# XMC4100 register map
Vendor: Infineon; File version: 1.5.2 (Reference Manual v1.5)
CPU: CM4 r2p0, little endian, MPU, FPU, 6 interrupt priority bits
Registers are 32-bit, read-write, reset 0x0 unless marked. A register's access mark holds for its fields unless they carry their own. Offsets are from the block's base; [hi:lo] are bit positions; {n}, {i} and the like mark numbered series; 'fields as' and 'values as' point back to an identical list.

## HRPWM0_CSG0 — High Resolution PWM Unit
Base 0x40020A00
Same registers: HRPWM0_CSG1 0x40020B00, HRPWM0_CSG2 0x40020C00
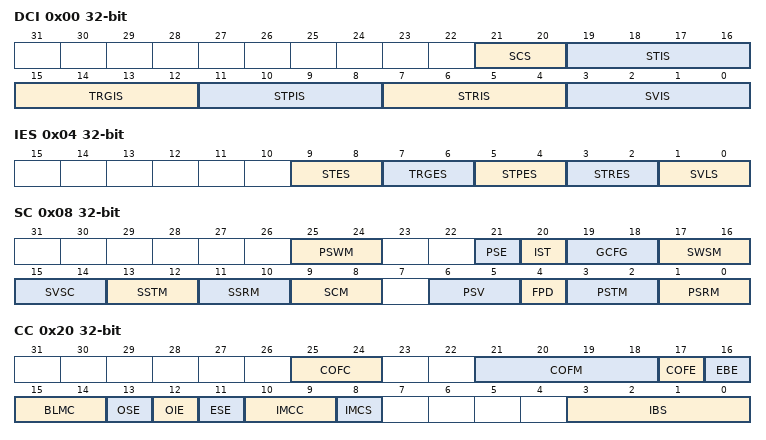
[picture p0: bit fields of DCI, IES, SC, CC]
0x00 DCI — External input selection
  [21:20] SCS — Slope generation clock selection
    0=HRPWMx.MCLK (Module clock is used); 1=HRPWMx.ECLKA (External clock is used); 2=HRPWMx.ECLKB (External clock is used); 3=HRPWMx.ECLKC (External clock is used)
  [19:16] STIS — External shadow request enable input selection
  [15:12] TRGIS — External conversion trigger input selection
  [11:8] STPIS — Slope generation stop control input selection
  [7:4] STRIS — Slope generation start control input selection
  [3:0] SVIS — Value Selector input selection
    0=HRPWMx.SyIA; 1=HRPWMx.SyIB; 2=HRPWMx.SyIC; 3=HRPWMx.SyID; 4=HRPWMx.SyIE; 5=HRPWMx.SyIF; 6=HRPWMx.SyIG; 7=HRPWMx.SyIH; 8=HRPWMx.SyII; 9=HRPWMx.SyIJ; 10=HRPWMx.SyIK; 11=HRPWMx.SyIL; 12=HRPWMx.SyIM; 13=HRPWMx.SyIN; 14=HRPWMx.SyIO; 15=HRPWMx.SyIP
0x04 IES — External input selection
  [9:8] STES — External shadow transfer enable edge selection
    0=Function disabled; 1=Active on rising edge; 2=Active on falling edge; 3=Active on both edges
  [7:6] TRGES — External trigger function edge selection
    values as STES
  [5:4] STPES — External stop function edge selection
    values as STES
  [3:2] STRES — External start function edge selection
    values as STES
  [1:0] SVLS — External value switch function level selection
    0=Function disabled; 1=Active when input is HIGH; 2=Active when input is LOW
0x08 SC — Slope generation control
  [25:24] PSWM — Pulse swallow window mode
    0=16 clock cycle window; 1=32 clock cycle window; 2=64 clock cycle window
  [21] PSE — Pulse swallow enable
    0=Pulse swallow disabled; 1=Pulse swallow enabled
  [20] IST — Immediate shadow transfer
  [19:18] GCFG — Slope step gain configuration
    0=Each slope step has an increment/decrement of 1; 1=Each slope step has an increment/decrement of 2; 2=Each slope step has an increment/decrement of 4; 3=Each slope step has an increment/decrement of 8
  [17:16] SWSM — Initial DAC start mode
    0=CSGyDSV2This register contains the actual value used for the DSV2 reference. is fed to the DAC and initial conversion trigger is generated.; 1=CSGyDSV1This register contains the actual value used for the DSV1 reference. is fed to the DAC and initial conversion trigger is generated.; 2=CSGyDSV2This register contains the actual value used for the DSV2 reference. is fed to the DAC but initial conversion trigger is not generated.; 3=CSGyDSV1This register contains the actual value used for the DSV1 reference. is fed to the DAC but initial conversion trigger is not generated.
  [15:14] SVSC — Slope reference value mode
    0=Only CSGyDSV1This register contains the actual value used for the DSV1 reference. value is used for the slope generation: if slope is incrementing, CSGyDSV1This register contains the actual value used for the DSV1 reference. is the bottom reference value from where the ramp starts; if decrementing, then CSGyDSV1This register contains the actual value used for the DSV1 reference. is the upper reference value from where the ramp starts.; 1=The two reference values are being used: CSGyDSV1This register contains the actual value used for the DSV1 reference. is the low or high reference value from where the ramp starts (incrementing or decrementing respectively); CSGyDSV2This register contains the actual value used for the DSV2 reference. is used as a static value (this value is constantly fed to the DAC after a stop trigger as been detected).; 2=The two reference values are used: CSGyDSV1This register contains the actual value used for the DSV1 reference. is the low or high reference value from where the slope starts (incrementing or decrementing respectively); CSGyDSV2This register contains the actual value used for the DSV2 reference. is used as an internal re start condition for the slope.
  [13:12] SSTM — Slope external stop configuration
    0=External stop trigger is ignored; 1=Stops/Halts the slope generation; 2=Used in hybrid mode. It freezes the slope generation and feeds constantly the value programmed in CSGyDSV2This register contains the actual value used for the DSV2 reference. to the DAC.
  [11:10] SSRM — Slope external start configuration
    0=External start trigger is ignored; 1=Start/restart slope generation; 2=Resumes slope
  [9:8] SCM — Slope control mode
    0=Slope generation disabled. Used when the switch between the two reference values, CSGyDSV1This register contains the actual value used for the DSV1 reference. and CSGyDSV2This register contains the actual value used for the DSV2 reference. is done via external signal.; 1=Decrementing slope generation; 2=Incrementing slope generation; 3=Triangular slope generation
  [6:5] PSV — Prescaler division factor
    0=division by 1; 1=division by 2; 2=division by 4; 3=division by 8
  [4] FPD — Fixed division disable
    0=Division by 4 enabled; 1=Division by 4 disabled
  [3:2] PSTM — Prescaler external stop configuration
    0=External stop trigger is ignored; 1=Stop prescaler; 2=Clear prescaler; 3=Clear & Stop prescaler
  [1:0] PSRM — Prescaler external start configuration
    0=External start trigger is ignored; 1=Start prescaler; 2=Clear prescaler; 3=Clear & Start prescaler
0x0C PC ro — Pulse swallow configuration
  [5:0] PSWV
0x10 DSV1 ro — DAC reference value 1
  [9:0] DSV1
0x14 DSV2 — DAC reference value 1
  [9:0] DSV2 — DAC reference value 2
0x18 SDSV1 — Shadow reference value 1
  [9:0] SDSV1 — Shadow DAC reference value 1
0x1C SPC — Shadow Pulse swallow value
  [5:0] SPSWV — Shadow pulse swallow value
0x20 CC — Comparator configuration
  [25:24] COFC — Comparator output filter control
    0=Filtering is always done if enabled; 1=Filtering is only done when CSGyDSV1 value is currently fed to the DAC; 2=Filtering is only done when the CSGyDSV2 value is currently fed to the DAC
  [21:18] COFM — Comparator output filter window
    {v}=Comparator Output needs to be stable for {v+2} clock cycles (v=0..3); 12=Comparator Output needs to be stable for 14 clock cycles; 13=Comparator Output needs to be stable for 15 clock cycles; 14=Comparator Output needs to be stable for 16 clock cycles; 15=Comparator Output needs to be stable for 32 clock cycles
  [17] COFE — Comparator output filter enable
    0=Filtering stage disabled; 1=Filtering stage enabled
  [16] EBE — External blanking trigger enabled
  [15:14] BLMC — Blanking mode
    0=Blanking disabled; 1=Blanking on a LOW to HIGH transition; 2=Blanking on a HIGH to LOW transition; 3=Blanking on both transitions
  [13] OSE — Comparator output synchronization enable
  [12] OIE — Comparator output inversion enable
  [11] ESE — External triggered switch enable
  [10:9] IMCC — Comparator input switching configuration
    0=Dynamic switch disabled; 1=Comparator input is connected to HRPWMx.CyINB when the control signal is HIGH; 2=Comparator input is connected to HRPWMx.CyINA when the control signal is HIGH
  [8] IMCS — Inverting comparator input selector
    0=HRPWMx.CyINA; 1=HRPWMx.CyINB
  [3:0] IBS — External blanking trigger selector
    0=HRPWMx.BLyA; 1=HRPWMx.BLyB; 2=HRPWMx.BLyC; 3=HRPWMx.BLyD; 4=HRPWMx.BLyE; 5=HRPWMx.BLyF; 6=HRPWMx.BLyG; 7=HRPWMx.BLyH; 8=HRPWMx.BLyI; 9=HRPWMx.BLyJ; 10=HRPWMx.BLyK; 11=HRPWMx.BLyL; 12=HRPWMx.BLyM; 13=HRPWMx.BLyN; 14=HRPWMx.BLyO; 15=HRPWMx.BLyP
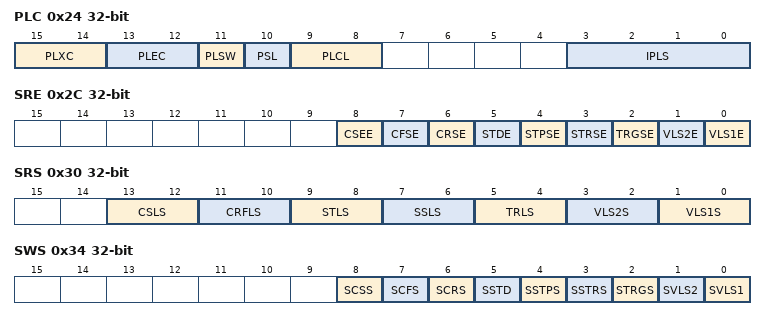
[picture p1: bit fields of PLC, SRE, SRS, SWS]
0x24 PLC — Passive level configuration
  [15:14] PLXC — Passive level exit configuration
    0=Passive level is exit immediately; 1=Passive level is exit only after the comparator output passes to LOW (output from the blanking stage); 2=Passive level is exit only after the comparator output passes to HIGH (output from the blanking stage)
  [13:12] PLEC — Passive level enter configuration
    0=Passive level is entered immediately; 1=Passive level is entered only after the comparator output passes to LOW (output from the blanking stage); 2=Passive level is entered only after the comparator output passes to HIGH (output from the blanking stage)
  [11] PLSW — Clamped state exit SW configuration
    0=External signal and SW can remove the output from the clamped state; 1=Only SW can remove the output from the clamped state
  [10] PSL — Output passive level value
    0=Output clamped level is LOW; 1=Output clamped level is HIGH
  [9:8] PLCL — Clamping control signal level selection
    0=Clamping control disabled; 1=Output is set to clamped level when the control signal is HIGH; 2=Output is set to clamped level when the control signal is LOW
  [3:0] IPLS — Clamping control signal selector
    values as CC.IBS
0x28 BLV — Comparator blanking value
  [7:0] BLV — Blanking value
0x2C SRE — Service request enable
  [8] CSEE — Clamped state interrupt enable
  [7] CFSE — Comparator fall interrupt enable
  [6] CRSE — Comparator rise interrupt enable
  [5] STDE — Shadow transfer done interrupt enable
  [4] STPSE — Stop trigger interrupt enable
  [3] STRSE — Start trigger interrupt enable
  [2] TRGSE — Conversion trigger interrupt enable
  [1] VLS2E — Value switch from CSGyDSV2 to CSGyDSV1 interrupt enable
  [0] VLS1E — Value switch from CSGyDSV1 to CSGyDSV2 interrupt enable
0x30 SRS — Service request line selector
  [all] fields
    {v}=CSGySR{v} (v=0..3)
  [13:12] CSLS — Comparator clamped state interrupt line selection
  [11:10] CRFLS — Comparator rise/fall interrupt line selection
  [9:8] STLS — Shadow transfer done interrupt line selection
  [7:6] SSLS — Start/Stop trigger interrupt line selection
  [5:4] TRLS — Conversion trigger interrupt line selection
  [3:2] VLS2S — Value switch from CSGyDSV2 to CSGyDSV1 interrupt line selection
  [1:0] VLS1S — Value switch from CSGyDSV1 to CSGyDSV2 interrupt line selection
0x34 SWS wo — Service request SW set
  [8] SCSS — Comparator clamped state status set
  [7] SCFS — Comparator fall status set
  [6] SCRS — Comparator rise status set
  [5] SSTD — Shadow transfer status set
  [4] SSTPS — Stop trigger status set
  [3] SSTRS — Start trigger status set
  [2] STRGS — Conversion trigger status set
  [1] SVLS2 — Value switch from CSGyDSV2 to CSGyDSV1 status set
  [0] SVLS1 — Value switch from CSGyDSV1 to CSGyDSV2 status set
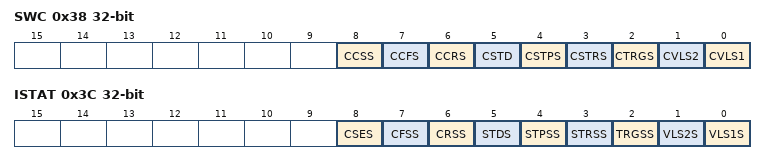
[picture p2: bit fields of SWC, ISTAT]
0x38 SWC wo — Service request SW clear
  [8] CCSS — Comparator clamped status clear
  [7] CCFS — Comparator fall status clear
  [6] CCRS — Comparator rise status clear
  [5] CSTD — Shadow transfer status clear
  [4] CSTPS — Stop trigger status clear
  [3] CSTRS — Start trigger status clear
  [2] CTRGS — Conversion trigger status clear
  [1] CVLS2 — Value switch from CSGyDSV2 to CSGyDSV1 status clear
  [0] CVLS1 — Value switch from CSGyDSV1 to CSGyDSV2 status clear
0x3C ISTAT ro — Service request status
  [8] CSES — Comparator clamped interrupt status
    0=Comparator output has been set to the clamped state; 1=Comparator output has not been set to the clamped state
  [7] CFSS — Comparator fall interrupt status
    0=Comparator output HIGH to LOW transition not detected; 1=Comparator output HIGH to LOW transition detected
  [6] CRSS — Comparator rise interrupt status
    0=Comparator output LOW to HIGH transition not detected; 1=Comparator output LOW to HIGH transition detected
  [5] STDS — Shadow transfer interrupt status
    0=Shadow transfer was not performed; 1=Shadow transfer was performed
  [4] STPSS — Stop trigger interrupt status
    0=Stop trigger not detected; 1=Stop trigger detected
  [3] STRSS — Start trigger interrupt status
    0=Start trigger not detected; 1=Start trigger detected
  [2] TRGSS — Conversion trigger status
    0=Conversion trigger was not generated; 1=Conversion trigger was generated
  [1] VLS2S — Value switch from CSGyDSV2 to CSGyDSV1 interrupt status
    0=Value switch not detected; 1=Value switch detected
  [0] VLS1S — Value switch from CSGyDSV1 to CSGyDSV2 interrupt status
    0=Value switch not detected; 1=Value switch detected
